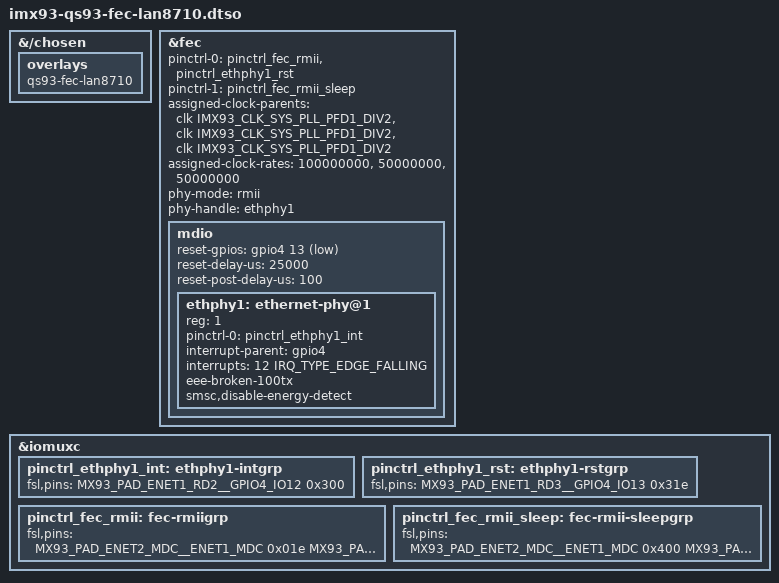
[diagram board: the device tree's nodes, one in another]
// SPDX-License-Identifier: (GPL-2.0 OR MIT)
/*
 * Copyright 2023 Lothar Waßmann <LW@KARO-electronics.de>
 * Copyright 2023 Markus Bauer <MB@KARO-electronics.de>
 *
 */

/dts-v1/;
/plugin/;

#include <dt-bindings/clock/imx93-clock.h>
#include <dt-bindings/gpio/gpio.h>
#include <dt-bindings/interrupt-controller/irq.h>
#include "imx93-pinfunc.h"

&{/chosen} {
	overlays {
		qs93-fec-lan8710;
	};
};

&fec {
	pinctrl-names = "default", "sleep";
	pinctrl-0 = <&pinctrl_fec_rmii &pinctrl_ethphy1_rst>;
	pinctrl-1 = <&pinctrl_fec_rmii_sleep>;
	assigned-clock-parents = <
		&clk IMX93_CLK_SYS_PLL_PFD1_DIV2
		&clk IMX93_CLK_SYS_PLL_PFD1_DIV2
		&clk IMX93_CLK_SYS_PLL_PFD1_DIV2
	>;
	assigned-clock-rates = <100000000>, <50000000>, <50000000>;
	phy-mode = "rmii";
	phy-handle = <&ethphy1>;
	status = "okay";

	mdio {
		reset-gpios = <&gpio4 13 GPIO_ACTIVE_LOW>;
		reset-delay-us = <25000>;
		reset-post-delay-us = <100>;

		ethphy1: ethernet-phy@1 {
			reg = <1>;
			pinctrl-names = "default";
			pinctrl-0 = <&pinctrl_ethphy1_int>;
			interrupt-parent = <&gpio4>;
			interrupts = <12 IRQ_TYPE_EDGE_FALLING>;
			eee-broken-100tx;
			smsc,disable-energy-detect;
		};
	};
};

&iomuxc {
	pinctrl_ethphy1_int: ethphy1-intgrp {
		fsl,pins = <
			MX93_PAD_ENET1_RD2__GPIO4_IO12				0x300
		>;
	};

	pinctrl_ethphy1_rst: ethphy1-rstgrp {
		fsl,pins = <
			MX93_PAD_ENET1_RD3__GPIO4_IO13				0x31e
		>;
	};

	pinctrl_fec_rmii: fec-rmiigrp {
		fsl,pins = <
			MX93_PAD_ENET2_MDC__ENET1_MDC				0x01e
			MX93_PAD_ENET2_MDIO__ENET1_MDIO				0x01e
			MX93_PAD_ENET2_TD2__ENET1_TX_CLK			0x4000011e
			MX93_PAD_ENET2_TD0__ENET1_RGMII_TD0			0x11e
			MX93_PAD_ENET2_TD1__ENET1_RGMII_TD1			0x11e
			MX93_PAD_ENET2_TX_CTL__ENET1_RGMII_TX_CTL		0x11e
			/* SMSC LAN8710 Strap pins: HIGH: 0x3.. LOW: 0x5.. */
			MX93_PAD_ENET2_RD0__ENET1_RGMII_RD0			0x300 /* MODE0 */
			MX93_PAD_ENET2_RD1__ENET1_RGMII_RD1			0x300 /* MODE1 */
			MX93_PAD_ENET2_RX_CTL__ENET1_RGMII_RX_CTL		0x300 /* MODE2 (ext. Pullup) */
			/* not used on RMII interface */
			MX93_PAD_ENET2_RXC__GPIO4_IO23				0x300 /* PHYAD0/RXER */
		>;
	};

	pinctrl_fec_rmii_sleep: fec-rmii-sleepgrp {
		fsl,pins = <
			MX93_PAD_ENET2_MDC__ENET1_MDC				0x400
			MX93_PAD_ENET2_MDIO__ENET1_MDIO				0x000
			MX93_PAD_ENET2_TD2__ENET1_TX_CLK			0x000
			MX93_PAD_ENET2_TD0__ENET1_RGMII_TD0			0x400
			MX93_PAD_ENET2_TD1__ENET1_RGMII_TD1			0x400
			MX93_PAD_ENET2_TX_CTL__ENET1_RGMII_TX_CTL		0x400
			MX93_PAD_ENET2_RD0__ENET1_RGMII_RD0			0x000
			MX93_PAD_ENET2_RD1__ENET1_RGMII_RD1			0x000
			MX93_PAD_ENET2_RX_CTL__ENET1_RGMII_RX_CTL		0x000
			MX93_PAD_ENET2_RXC__GPIO4_IO23				0x000
		>;
	};
};
